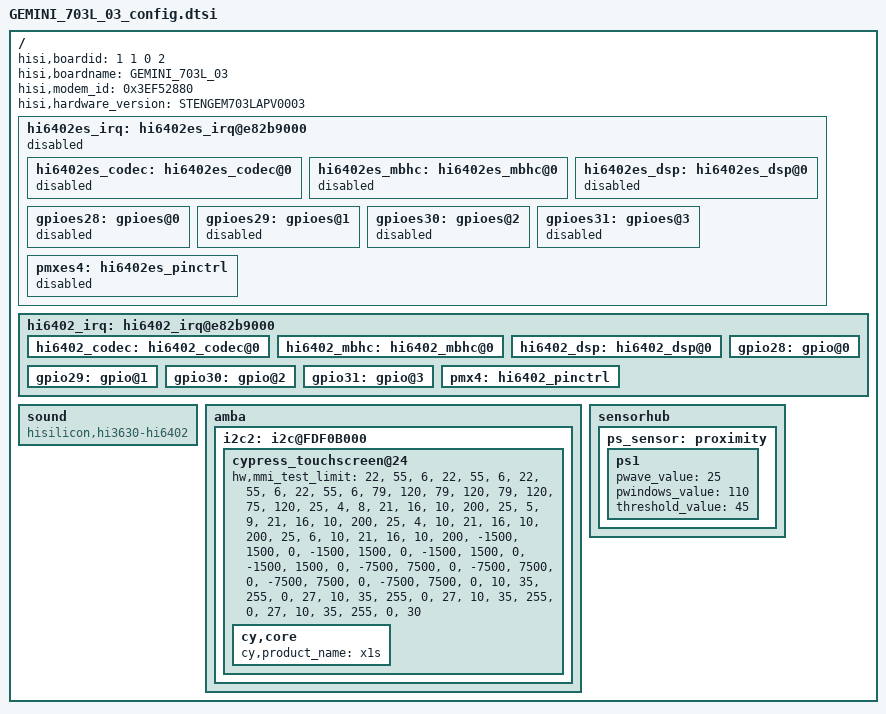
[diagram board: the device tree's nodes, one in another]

/**
 * Huawei Ltd.
 * PhosphorV660
 */


/include/ "fastboot.dtsi"
/include/ "GEMINI_703L_01_config.dtsi"
/include/ "GEMINI_703L_03_pin.dtsi"
/include/ "GEMINI_703L_03_hi6402_pin.dtsi"
/include/ "GEMINI_703L_03_modem_pin.dtsi"
///include/ "GEMINI_703L_03_charger.dtsi"
///include/ "GEMINI_703L_03_pmic.dtsi"
///include/ "GEMINI_703L_03_gpio_logic.dtsi"

/ {
	hisi,boardid = <1 1 0 2 >;
	hisi,boardname = "GEMINI_703L_03";
	hisi,modem_id = <0x3EF52880>;
	hisi,hardware_version="STENGEM703LAPV0003";

	hi6402es_irq: hi6402es_irq@e82b9000 {
		status = "disabled";
		hi6402es_codec: hi6402es_codec@0{
			status = "disabled";
		};

		hi6402es_mbhc: hi6402es_mbhc@0{
			status = "disabled";
		};

		hi6402es_dsp: hi6402es_dsp@0{
			status = "disabled";
		};

		gpioes28: gpioes@0{
			status = "disabled";
		};

		gpioes29: gpioes@1{
			status = "disabled";
		};

		gpioes30: gpioes@2{
			status = "disabled";
		};

		gpioes31: gpioes@3{
			status = "disabled";
		};

		pmxes4: hi6402es_pinctrl {
			status = "disabled";
		};
	};

	hi6402_irq: hi6402_irq@e82b9000 {
		status = "ok";
		hi6402_codec: hi6402_codec@0{
			status = "ok";
		};

		hi6402_mbhc: hi6402_mbhc@0{
			status = "ok";
		};

		hi6402_dsp: hi6402_dsp@0{
			status = "ok";
		};

		gpio28: gpio@0{
			status = "ok";
		};

		gpio29: gpio@1{
			status = "ok";
		};

		gpio30: gpio@2{
			status = "ok";
		};

		gpio31: gpio@3{
			status = "ok";
		};

		pmx4: hi6402_pinctrl {
			status = "ok";
		};
	};

	sound {
		compatible = "hisilicon,hi3630-hi6402";
		status = "ok";
	};
	amba {
		i2c2: i2c@FDF0B000 {
			cypress_touchscreen@24 {
			    hw,mmi_test_limit =
			                 "22","55","6","22","55","6","22","55","6","22","55","6",                     /*mmi_idac_limit*/
					 "79","120","79","120","79","120","75","120",                                 /*mmi_localPWC_limit*/
					 "25","4","8", "21","16","10","200","25","5","9", "21","16","10","200",       /*mmi_opens_limit*/
					 "25","4","10","21","16","10","200","25","6","10","21","16","10","200",       /*mmi_opens_limit*/
					 "-1500","1500","0","-1500","1500","0","-1500","1500","0","-1500","1500","0", /*mmi_mut_rawdata_limit*/
					 "-7500","7500","0","-7500","7500","0","-7500","7500","0","-7500","7500","0", /*mmi_self_rawdata_limit*/
					 "10","35","255","0","27","10","35","255","0","27",                           /*mmi_selflocalPWC_limit*/
					 "10","35","255","0","27","10","35","255","0","30";/*mmi_selflocalPWC_limit*/
				cy,core {
					cy,product_name = "x1s";
				};
		    };
		};
	};
	//old tp
	sensorhub{
		ps_sensor:proximity{
			ps1{
				pwave_value=<25>;
				pwindows_value=<110>;
				threshold_value=<45>;
			};
		};
	};
};

